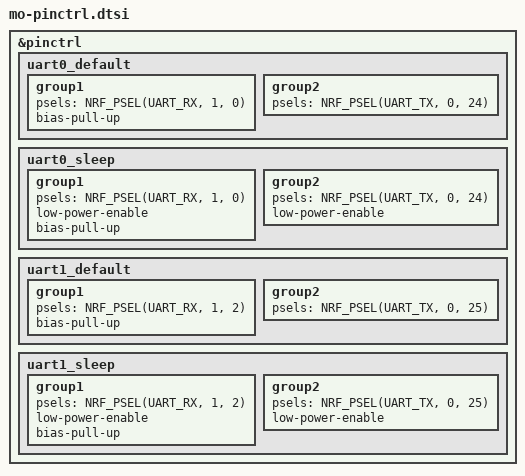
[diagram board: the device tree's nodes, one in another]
/*
 * SPDX-License-Identifier: Apache-2.0
 */

&pinctrl {
	uart0_default: uart0_default {
		group1 {
			psels = <NRF_PSEL(UART_RX, 1, 0)>;
			bias-pull-up;
		};

		group2 {
			psels = <NRF_PSEL(UART_TX, 0, 24)>;
		};
	};

	uart0_sleep: uart0_sleep {
		group1 {
			psels = <NRF_PSEL(UART_RX, 1, 0)>;
			low-power-enable;
			bias-pull-up;
		};

		group2 {
			psels = <NRF_PSEL(UART_TX, 0, 24)>;
			low-power-enable;
		};
	};

	uart1_default: uart1_default {
		group1 {
			psels = <NRF_PSEL(UART_RX, 1, 2)>;
			bias-pull-up;
		};

		group2 {
			psels = <NRF_PSEL(UART_TX, 0, 25)>;
		};
	};

	uart1_sleep: uart1_sleep {
		group1 {
			psels = <NRF_PSEL(UART_RX, 1, 2)>;
			low-power-enable;
			bias-pull-up;
		};

		group2 {
			psels = <NRF_PSEL(UART_TX, 0, 25)>;
			low-power-enable;
		};
	};
};
